# ESP32-S31 register map
Vendor: ESPRESSIF SYSTEMS (SHANGHAI) CO., LTD.; Series: ESP32 S-Series; File version: 1
CPU: RV32IMAFC r0p0, little endian, no MPU, FPU, 0 interrupt priority bits
Address unit: 32 bits
Registers are 32-bit, read-write, reset 0x0 unless marked. A register's access mark holds for its fields unless they carry their own. Offsets are from the block's base; [hi:lo] are bit positions; lines under a group give offsets from that group; {n}, {i} and the like mark numbered series.

## GMAC (part 2 of 2) — Ethernet MAC
Base 0x20350000
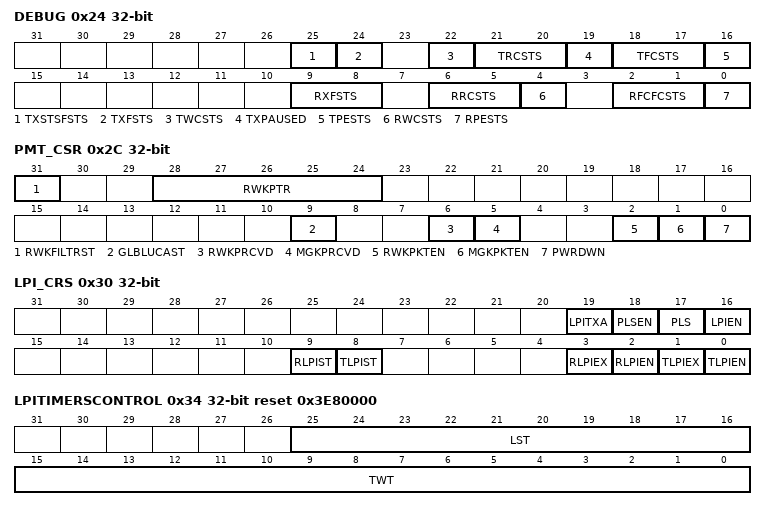
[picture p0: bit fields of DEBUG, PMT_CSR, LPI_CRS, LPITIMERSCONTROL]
0x24 DEBUG ro — Status debugging bits
  [25] TXSTSFSTS — MTL TxStatus FIFO Full Status When high, this bit indicates that the MTL TxStatus FIFO is full Therefore, the MTL cannot accept any more frames for transmission This bit is reserved in the GMACAHB and GMACDMA configurations
  [24] TXFSTS — MTL Tx FIFO Not Empty Status When high, this bit indicates that the MTL Tx FIFO is not empty and some data is left for transmission
  [22] TWCSTS — MTL Tx FIFO Write Controller Status When high, this bit indicates that the MTL Tx FIFO Write Controller is active and is transferring data to the Tx FIFO
  [21:20] TRCSTS — MTL Tx FIFO Read Controller Status This field indicates the state of the Tx FIFO Read Controller: 00: IDLE state 01: READ state _transferring data to the MAC transmitter_ 10: Waiting for TxStatus from the MAC transmitter 11: Writing the received TxStatus or flushing the Tx FIFO
  [19] TXPAUSED — MAC Transmitter in Pause When high, this bit indicates that the MAC transmitter is in the Pause condition _in the fullduplexonly mode_ and hence does not schedule any frame for transmission
  [18:17] TFCSTS — MAC Transmit Frame Controller Status This field indicates the state of the MAC Transmit Frame Controller module: 00: IDLE state 01: Waiting for status of previous frame or IFG or backoff period to be over 10: Generating and transmitting a Pause frame _in the fullduplex mode_ 11: Transferring input frame for transmission
  [16] TPESTS — MAC GMII or MII Transmit Protocol Engine Status When high, this bit indicates that the MAC GMII or MII transmit protocol engine is actively transmitting data and is not in the IDLE state
  [9:8] RXFSTS — MTL RxFIFO FillLevel Status This field gives the status of the filllevel of the Rx FIFO: 00: Rx FIFO Empty 01: Rx FIFO filllevel below flowcontrol deactivate threshold 10: Rx FIFO filllevel above flowcontrol activate threshold 11: Rx FIFO Full
  [6:5] RRCSTS — MTL RxFIFO Read Controller State This field gives the state of the Rx FIFO read Controller: 00: IDLE state 01: Reading frame data 10: Reading frame status _or timestamp_ 11: Flushing the frame data and status
  [4] RWCSTS — MTL Rx FIFO Write Controller Active Status When high, this bit indicates that the MTL Rx FIFO Write Controller is active and is transferring a received frame to the FIFO
  [2:1] RFCFCSTS — MAC Receive Frame FIFO Controller Status When high, this field indicates the active state of the small FIFO Read and Write controllers of the MAC Receive Frame Controller Module RFCFCSTS[1] represents the status of small FIFO Read controller RFCFCSTS[0] represents the status of small FIFO Write controller
  [0] RPESTS — MAC GMII or MII Receive Protocol Engine Status When high, this bit indicates that the MAC GMII or MII receive protocol engine is actively receiving data and not in IDLE state
0x28 PMT_RWUFFR ro — Remote Wake-Up Frame Filter Register
  [31:0] WKUPFRM_FILTER rw — This is the address through which the application writes or reads the remote wake-up frame filter registers.The reg_wkupfrm_filter register is a pointer to eight reg_wkupfrm_filter registers.The reg_wkupfrm_filter register is loaded by sequentially loading the eight register values.Eight sequential writes to this address(0x0028)write all reg_wkupfrm_filter registers.Similarly, eight sequential reads from this address(0x0028) read all reg_wkupfrm_filter registers. This register is present only when you select the PMT module Remote Wake-Up feature in coreConsultant.
0x2C PMT_CSR ro — PMT Control and Status
  [31] RWKFILTRST rw — Remote Wake-Up Frame Filter Register Pointer Reset. When this bit is set, it resets the remote wake-up frame filter register pointer to 3'b000. It is automatically cleared after 1 clock cycle.
  [28:24] RWKPTR — Remote Wake-up FIFO Pointer. This field gives the current value(0 to 31) of the Remote Wake-up Frame filter register pointer. When the value of this pointer is erual to 7, 15, 23 or 31, the contents of the Remote Wake-up Frame Filter Register are transferred to the clk_rx_i domain when a write occurs to that register. The maximum value of the pointer is 7, 15, 23 and 31 respectively depending on the number of Remote Wakeup Filters selected during configuration.
  [9] GLBLUCAST rw — Global Unicast. When set, enables any unicast packet filtered by the MAX(DAF) address recognition to be a remote wake-up frame.
  [6] RWKPRCVD rw — Remote Wake-Up Frame Received When set, this bit indicates the power management event is generated because of the reception of a remote wake-up frame. This bit is cleared by a Read into this register.
  [5] MGKPRCVD rw — Magic Packet Received When set,this bit indicates that the power management event is generated because of the reception of a magic packet. This bit is cleared by Read into this register.
  [2] RWKPKTEN rw — Remote Wake-Up Frame Enable When set, enables generation of a power management event because of remote wake-up frame reception.
  [1] MGKPKTEN rw — Magic Packet Enable When set, enables generation of a power management event because of magic packet reception.
  [0] PWRDWN rw — Power Down When set, the MAC receiver drops all received frames until it receives the expected magic packet or remote wake-up frame. This bit is then self-cleared and the power-down mode is disabled. The Software can also clear this bit before the expected magic packet or remote wake-up frame is received. The frames, received by MAC after this bit is cleared, are forwarded to the application. This bit must only be set when the Magic Packet Enable, Global Unicast, or Remote Wake-Up Frame Enable bit is set high.
0x30 LPI_CRS ro — LPI Control and Status
  [19] LPITXA rw — LPI TX Automate This bit controls the behavior of the MAC when it is entering or coming out of the LPI mode on the transmit side This bit is not functional in the GMAC CORE configuration in which the Tx clock gating is done during the LPI mode If the LPITXA and LPIEN bits are set to 1, the MAC enters the LPI mode only after all outstanding frames _in the core_ and pending frames _in the application interface_ have been transmitted The MAC comes out of the LPI mode when the application sends any frame for transmission or the application issues a TX FIFO Flush command In addition, the MAC automatically clears the LPIEN bit when it exits the LPI state If TX FIFO Flush is set in Bit 20 of Register 6 _Operation Mode Register_, when the MAC is in the LPI mode, the MAC exits the LPI mode When this bit is 0, the LPIEN bit directly controls behavior of the MAC when it is entering or coming out of the LPI mode
  [18] PLSEN rw — PHY Link Status Enable This bit enables the link status received on the RGMII, SGMII, or SMII receive paths to be used for activating the LPI LS TIMER When set, the MAC uses the linkstatus bits of Register 54 _SGMII/RGMII/SMII Control and Status Register_ and Bit 17 _PLS_ for the LPI LS Timer trigger When cleared, the MAC ignores the linkstatus bits of Register 54 and takes only the PLS bit This bit is RO and reserved if you have not selected the RGMII, SGMII, or SMII PHY interface
  [17] PLS rw — PHY Link Status This bit indicates the link status of the PHY The MAC Transmitter asserts the LPI pattern only when the link status is up _okay_ at least for the time indicated by the LPI LS TIMER When set, the link is considered to be okay _up_ and when reset, the link is considered to be down
  [16] LPIEN rw — LPI Enable When set, this bit instructs the MAC Transmitter to enter the LPI state When reset, this bit instructs the MAC to exit the LPI state and resume normal transmission This bit is cleared when the LPITXA bit is set and the MAC exits the LPI state because of the arrival of a new packet for transmission
  [9] RLPIST — Receive LPI State When set, this bit indicates that the MAC is receiving the LPI pattern on the GMII or MII interface
  [8] TLPIST — Transmit LPI State When set, this bit indicates that the MAC is transmitting the LPI pattern on the GMII or MII interface
  [3] RLPIEX rw — Receive LPI Exit When set, this bit indicates that the MAC Receiver has stopped receiving the LPI pattern on the GMII or MII interface, exited the LPI state, and resumed the normal reception This bit is cleared by a read into this register Note: This bit may not get set if the MAC stops receiving the LPI pattern for a very short duration, such as, less than 3 clock cycles of CSR clock
  [2] RLPIEN rw — Receive LPI Entry When set, this bit indicates that the MAC Receiver has received an LPI pattern and entered the LPI state This bit is cleared by a read into this register Note: This bit may not get set if the MAC stops receiving the LPI pattern for a very short duration, such as, less than 3 clock cycles of CSR clock
  [1] TLPIEX rw — Transmit LPI Exit When set, this bit indicates that the MAC transmitter has exited the LPI state after the user has cleared the LPIEN bit and the LPI TW Timer has expired This bit is cleared by a read into this register
  [0] TLPIEN rw — Transmit LPI Entry When set, this bit indicates that the MAC Transmitter has entered the LPI state because of the setting of the LPIEN bit This bit is cleared by a read into this register
0x34 LPITIMERSCONTROL ro reset 0x3E80000
  [25:16] LST rw — LPI LS TIMER This field specifies the minimum time _in milliseconds_ for which the link status from the PHY should be up _OKAY_ before the LPI pattern can be transmitted to the PHY The MAC does not transmit the LPI pattern even when the LPIEN bit is set unless the LPI LS Timer reaches the programmed terminal count The default value of the LPI LS Timer is 1000 _1 sec_ as defined in the IEEE standard
  [15:0] TWT rw — LPI TW TIMER This field specifies the minimum time _in microseconds_ for which the MAC waits after it stops transmitting the LPI pattern to the PHY and before it resumes the normal transmission The TLPIEX status bit is set after the expiry of this timer
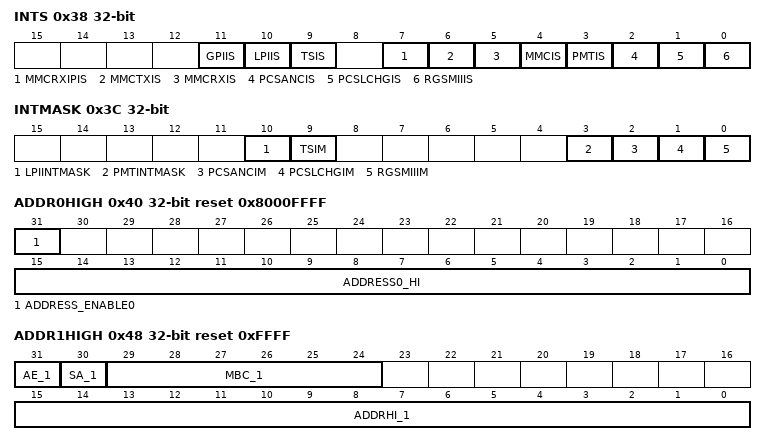
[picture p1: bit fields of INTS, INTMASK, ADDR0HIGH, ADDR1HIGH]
0x38 INTS ro — Interrupt status
  [11] GPIIS — GPI Interrupt Status When the GPIO feature is enabled, this bit is set when any active event _LL or LH_ occurs on the GPIS field _Bits [3:0]_ of Register 56 _General Purpose IO Register_ and the corresponding GPIE bit is enabled This bit is cleared on reading lane 0 _GPIS_ of Register 56 _General Purpose IO Register_ When the GPIO feature is not enabled, this bit is reserved
  [10] LPIIS — LPI Interrupt Status When the Energy Efficient Ethernet feature is enabled, this bit is set for any LPI state entry or exit in the MAC Transmitter or Receiver This bit is cleared on reading Bit 0 of Register 12 _LPI Control and Status Register_ In all other modes, this bit is reserved
  [9] TSIS — Timestamp Interrupt Status When the Advanced Timestamp feature is enabled, this bit is set when R_SS_RC any of the following conditions is true: The system time value equals or exceeds the value specified in the Target Time High and Low registers There is an overflow in the seconds register The Auxiliary snapshot trigger is asserted This bit is cleared on reading Bit 0 of Register 458 _Timestamp Status Register_ If default Timestamping is enabled, when set, this bit indicates that the system time value is equal to or exceeds the value specified in the Target Time registers In this mode, this bit is cleared after the completion of the read of this bit In all other modes, this bit is reserved
  [7] MMCRXIPIS — MMC Receive Checksum Offload Interrupt Status This bit is set high when an interrupt is generated in the MMC Receive Checksum Offload Interrupt Register This bit is cleared when all the bits in this interrupt register are cleared This bit is valid only when you select the optional MMC module and Checksum Offload Engine _Type 2_ during core configuration
  [6] MMCTXIS — MMC Transmit Interrupt Status This bit is set high when an interrupt is generated in the MMC Transmit Interrupt Register This bit is cleared when all the bits in this interrupt register are cleared This bit is valid only when you select the optional MMC module during core configuration
  [5] MMCRXIS — MMC Receive Interrupt Status This bit is set high when an interrupt is generated in the MMC Receive Interrupt Register This bit is cleared when all the bits in this interrupt register are cleared This bit is valid only when you select the optional MMC module during core configuration
  [4] MMCIS — MMC Interrupt Status This bit is set high when any of the Bits [7:5] is set high and cleared only when all of these bits are low This bit is valid only when you select the optional MMC module during core configuration
  [3] PMTIS — PMT Interrupt Status This bit is set when a magic packet or remote wakeup frame is received in the powerdown mode _see Bits 5 and 6 in the PMT Control and Status Register_ This bit is cleared when both Bits[6:5] are cleared because of a read operation to the PMT Control and Status register This bit is valid only when you select the optional PMT module during core configuration
  [2] PCSANCIS — PCS AutoNegotiation Complete This bit is set when the Autonegotiation is completed in the TBI, RTBI, or SGMII PHY interface _Bit 5 in Register 49 _AN Status Register__ This bit is cleared when you perform a read operation to the AN Status register This bit is valid only when you select the optional TBI, RTBI, or SGMII PHY interface during core configuration and operation
  [1] PCSLCHGIS — PCS Link Status Changed This bit is set because of any change in Link Status in the TBI, RTBI, or SGMII PHY interface _Bit 2 in Register 49 _AN Status Register__ This bit is cleared when you perform a read operation on the AN Status register This bit is valid only when you select the optional TBI, RTBI, or SGMII PHY interface during core configuration and operation
  [0] RGSMIIIS — RGMII or SMII Interrupt Status This bit is set because of any change in value of the Link Status of RGMII or SMII interface _Bit 3 in Register 54 _SGMII/RGMII/SMII Control and Status Register__ This bit is cleared when you perform a read operation on the SGMII/RGMII/SMII Control and Status Register This bit is valid only when you select the optional RGMII or SMII PHY interface during core configuration and operation
0x3C INTMASK — Interrupt mask
  [10] LPIINTMASK — LPI Interrupt Mask When set, this bit disables the assertion of the interrupt signal because of the setting of the LPI Interrupt Status bit in Register 14 _Interrupt Status Register_ This bit is valid only when you select the Energy Efficient Ethernet feature during core configuration In all other modes, this bit is reserved
  [9] TSIM — Timestamp Interrupt Mask When set, this bit disables the assertion of the interrupt signal because of the setting of Timestamp Interrupt Status bit in Register 14 _Interrupt Status Register_ This bit is valid only when IEEE1588 timestamping is enabled In all other modes, this bit is reserved
  [3] PMTINTMASK — PMT Interrupt Mask When set, this bit disables the assertion of the interrupt signal because of the setting of PMT Interrupt Status bit in Register 14 _Interrupt Status Register_
  [2] PCSANCIM — PCS AN Completion Interrupt Mask When set, this bit disables the assertion of the interrupt signal because of the setting of PCS Autonegotiation complete bit in Register 14 _Interrupt Status Register_
  [1] PCSLCHGIM — PCS Link Status Interrupt Mask When set, this bit disables the assertion of the interrupt signal because of the setting of the PCS Linkstatus changed bit in Register 14 _Interrupt Status Register_
  [0] RGSMIIIM — RGMII or SMII Interrupt Mask When set, this bit disables the assertion of the interrupt signal because of the setting of the RGMII or SMII Interrupt Status bit in Register 14 _Interrupt Status Register_
0x40 ADDR0HIGH reset 0x8000FFFF — Upper 16 bits of the first 6-byte MAC address
  [31] ADDRESS_ENABLE0 — Address Enable This bit is always set to 1
  [15:0] ADDRESS0_HI — MAC Address0 [47:32] This field contains the upper 16 bits _47:32_ of the first 6byte MAC address The MAC uses this field for filtering the received frames and inserting the MAC address in the Transmit Flow Control _Pause_ Frames
0x44 ADDR0LOW access not given reset 0xFFFFFFFF — Contains the lower 32 bits of the first MAC address
0x48 ADDR1HIGH reset 0xFFFF — Upper 16 bits of the second 6-byte MAC address
  [31] AE_1 — Address Enable
  [30] SA_1 — Source Address When this bit is set, the MAC Address1[47:0] is used to compare with the SA fields of the received frame When this bit is reset, the MAC Address1[47:0] is used to compare with the DA fields of the received frame
  [29:24] MBC_1 — Mask Byte Control These bits are mask control bits for comparison of each of the MAC Address bytes When set high, the MAC does not compare the corresponding byte of received DA or SA with the contents of MAC Address1 registers Each bit controls the masking of the bytes as follows: Bit 29: Register 18[15:8] Bit 28: Register 18[7:0] Bit 27: Register 19[31:24] Bit 24: Register 19[7:0] You can filter a group of addresses _known as group address filtering_ by masking one or more bytes of the address
  [15:0] ADDRHI_1 — MAC Address1 [47:32] This field contains the upper 16 bits _47:32_ of the second 6byte MAC address
0x4C ADDR1LOW reset 0xFFFFFFFF — Contains the lower 32 bits of the second MAC address This register is present only when Enable MAC Address1 is selected in coreConsultant _See Table 78_
  [31:0] ADDRLO_1 — MAC Address1 [31:0] This field contains the lower 32 bits of the second 6byte MAC address The content of this field is undefined until loaded by the Application after the initialization process
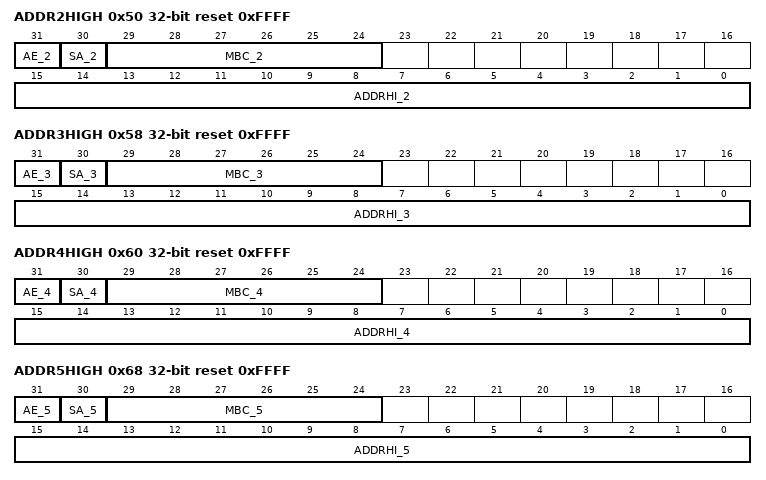
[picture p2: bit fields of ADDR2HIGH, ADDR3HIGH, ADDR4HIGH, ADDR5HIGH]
0x50 ADDR2HIGH reset 0xFFFF — Upper 16 bits of the third 6-byte MAC address
  [31] AE_2 — This register is present only when Enable MAC Address2 is selected in coreConsultant _See Table 78_
  [30] SA_2 — This register is present only when Enable MAC Address2 is selected in coreConsultant _See Table 78_
  [29:24] MBC_2 — This register is present only when Enable MAC Address2 is selected in coreConsultant _See Table 78_
  [15:0] ADDRHI_2 — This register is present only when Enable MAC Address2 is selected in coreConsultant _See Table 78_
{0x44+8i} ADDR{i}LOW reset 0xFFFFFFFF (i=2..7) — Reserved
  [31:0] ADDRLO_{i} — This register is present only when Enable MAC Address{i} is selected in coreConsultant _See Table 78_
0x58 ADDR3HIGH reset 0xFFFF — Upper 16 bits of the fourth 6-byte MAC address
  [31] AE_3 — This register is present only when Enable MAC Address3 is selected in coreConsultant _See Table 78_
  [30] SA_3 — This register is present only when Enable MAC Address3 is selected in coreConsultant _See Table 78_
  [29:24] MBC_3 — This register is present only when Enable MAC Address3 is selected in coreConsultant _See Table 78_
  [15:0] ADDRHI_3 — This register is present only when Enable MAC Address3 is selected in coreConsultant _See Table 78_
0x60 ADDR4HIGH reset 0xFFFF — Upper 16 bits of the fifth 6-byte MAC address
  [31] AE_4 — This register is present only when Enable MAC Address4 is selected in coreConsultant _See Table 78_
  [30] SA_4 — This register is present only when Enable MAC Address4 is selected in coreConsultant _See Table 78_
  [29:24] MBC_4 — This register is present only when Enable MAC Address4 is selected in coreConsultant _See Table 78_
  [15:0] ADDRHI_4 — This register is present only when Enable MAC Address4 is selected in coreConsultant _See Table 78_
0x68 ADDR5HIGH reset 0xFFFF — Upper 16 bits of the sixth 6-byte MAC address
  [31] AE_5 — This register is present only when Enable MAC Address5 is selected in coreConsultant _See Table 78_
  [30] SA_5 — This register is present only when Enable MAC Address5 is selected in coreConsultant _See Table 78_
  [29:24] MBC_5 — This register is present only when Enable MAC Address5 is selected in coreConsultant _See Table 78_
  [15:0] ADDRHI_5 — This register is present only when Enable MAC Address5 is selected in coreConsultant _See Table 78_
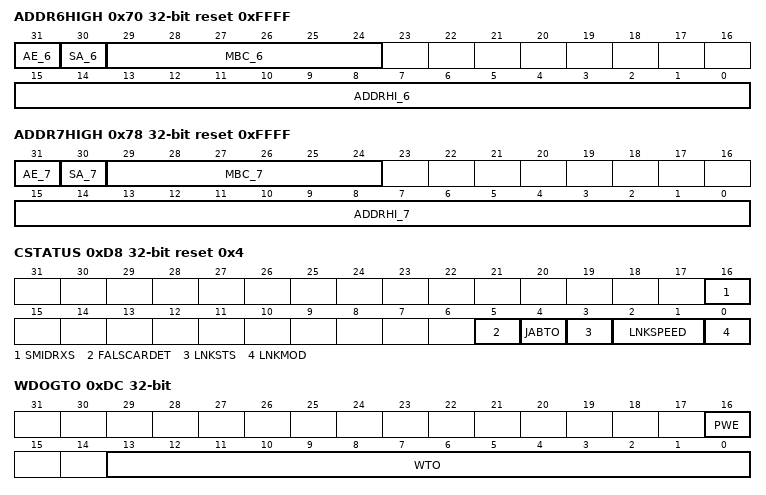
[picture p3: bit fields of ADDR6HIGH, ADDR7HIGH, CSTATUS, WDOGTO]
0x70 ADDR6HIGH reset 0xFFFF — Upper 16 bits of the seventh 6-byte MAC address
  [31] AE_6 — This register is present only when Enable MAC Address6 is selected in coreConsultant _See Table 78_
  [30] SA_6 — This register is present only when Enable MAC Address6 is selected in coreConsultant _See Table 78_
  [29:24] MBC_6 — This register is present only when Enable MAC Address6 is selected in coreConsultant _See Table 78_
  [15:0] ADDRHI_6 — This register is present only when Enable MAC Address6 is selected in coreConsultant _See Table 78_
0x78 ADDR7HIGH reset 0xFFFF — Upper 16 bits of the eighth 6-byte MAC address
  [31] AE_7 — This register is present only when Enable MAC Address7 is selected in coreConsultant _See Table 78_
  [30] SA_7 — This register is present only when Enable MAC Address7 is selected in coreConsultant _See Table 78_
  [29:24] MBC_7 — This register is present only when Enable MAC Address7 is selected in coreConsultant _See Table 78_
  [15:0] ADDRHI_7 — This register is present only when Enable MAC Address7 is selected in coreConsultant _See Table 78_
0xD8 CSTATUS ro reset 0x4 — Link communication status
  [16] SMIDRXS rw — Delay SMII RX Data Sampling with respect to the SMII SYNC Signal When set, the first bit of the SMII RX data is sampled one cycle after the SMII SYNC signal When reset, the first bit of the SMII RX data is sampled along with the SMII SYNC signal If the SMII PHY Interface with source synchronous mode is selected during core configuration, this bit is reserved _RO with default value_
  [5] FALSCARDET — False Carrier Detected This bit indicates whether the SMII PHY detected false carrier _1'b1_ This bit is reserved when the MAC is configured for the SGMII or RGMII PHY interface
  [4] JABTO — Jabber Timeout This bit indicates whether there is jabber timeout error _1'b1_ in the received frame This bit is reserved when the MAC is configured for the SGMII or RGMII PHY interface
  [3] LNKSTS — Link Status This bit indicates whether the link between the local PHY and the remote PHY is up or down It gives the status of the link between the SGMII of MAC and the SGMII of the local PHY The status bits are received from the local PHY during ANEG betweent he MAC and PHY on the SGMII link
  [2:1] LNKSPEED — Link Speed
  [0] LNKMOD — Link Mode This bit indicates the current mode of operation of the link: 1’b0: Halfduplex mode 1’b1: Fullduplex mode
0xDC WDOGTO — Watchdog timeout control
  [16] PWE — Programmable Watchdog Enable When this bit is set and Bit 23 _WD_ of Register 0 _MAC Configuration Register_ is reset, the WTO field _Bits[13:0]_ is used as watchdog timeout for a received frame When this bit is cleared, the watchdog timeout for a received frame is controlled by the setting of Bit 23 _WD_ and Bit 20 _JE_ in Register 0 _MAC Configuration Register_
  [13:0] WTO — Watchdog Timeout When Bit 16 _PWE_ is set and Bit 23 _WD_ of Register 0 _MAC Configuration Register_ is reset, this field is used as watchdog timeout for a received frame If the length of a received frame exceeds the value of this field, such frame is terminated and declared as an error frame Note: When Bit 16 _PWE_ is set, the value in this field should be more than 1,522 _0x05F2_ Otherwise, the IEEE Std 8023specified valid tagged frames are declared as error frames and are dropped
